# EFR32FG23B010F512IM48 register map
Vendor: Silicon Labs; Series: EFR32; File version: C
CPU: CM33 r0p4, little endian, MPU, FPU, DSP, VTOR, 4 interrupt priority bits, 8 SAU regions
Registers are 32-bit, read-write, reset 0x0 unless marked. A register's access mark holds for its fields unless they carry their own. Offsets are from the block's base; [hi:lo] are bit positions; 'fields as' and 'values as' point back to an identical list.

## DCDC_NS — DCDC_NS Registers
Base 0x50094000
Same registers: DCDC_S 0x40094000
0x00 IPVERSION ro reset 0x1
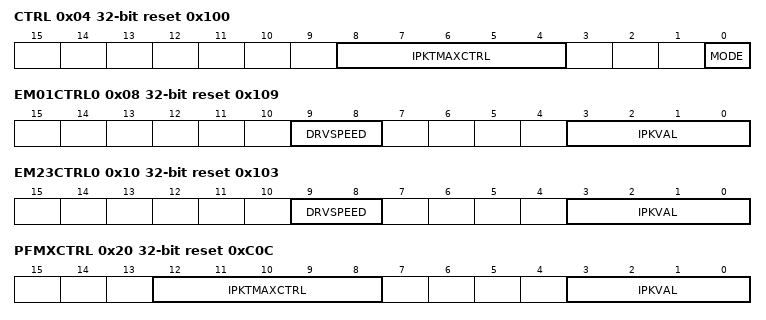
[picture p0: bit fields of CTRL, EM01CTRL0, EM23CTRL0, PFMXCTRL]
0x04 CTRL reset 0x100 — Control
  [8:4] IPKTMAXCTRL — Ton_max timeout control
  [0] MODE — DCDC/Bypass Mode Control
    0=BYPASS (DCDC is OFF, bypass switch is enabled); 1=DCDCREGULATION (Request DCDC regulation, bypass switch disabled)
0x08 EM01CTRL0 reset 0x109 — EM01 Configurations
  [9:8] DRVSPEED — EM01 Drive Speed Setting
    0=BEST_EMI (Not recommended for use (no benefit to this setting)); 1=DEFAULT_SETTING (Recommended for use for best efficiency and low EMI); 2=INTERMEDIATE (Not recommended for use (no benefit to this setting)); 3=BEST_EFFICIENCY (Not recommended for use (no benefit to this setting))
  [3:0] IPKVAL — EM01 Peak Current Setting
    3=Load36mA (Ipeak = 90mA, Iload = 36mA); 4=Load40mA (Ipeak = 100mA, Iload = 40mA); 5=Load44mA (Ipeak = 110mA, Iload = 44mA); 6=Load48mA (Ipeak = 120mA, Iload = 48mA); 7=Load52mA (Ipeak = 130mA, Iload = 52mA); 8=Load56mA (Ipeak = 140mA, Iload = 56mA); 9=Load60mA (Ipeak = 150mA, Iload = 60mA)
0x10 EM23CTRL0 reset 0x103 — EM23 Configurations
  [9:8] DRVSPEED — EM23 Drive Speed Setting
    values as EM01CTRL0.DRVSPEED
  [3:0] IPKVAL — EM23 Peak Current Setting
    3=Load5mA (Ipeak = 90mA, Iload = 5 mA); 9=Load10mA (Ipeak = 150mA, Iload = 10 mA)
0x20 PFMXCTRL reset 0xC0C — PFMX Control Register
  [12:8] IPKTMAXCTRL — Ton_max timeout control
  [3:0] IPKVAL — PFMX mode Peak Current Setting
    3=LOAD50MA (Ipeak = 90 mA, Iload = 50 mA); 4=LOAD65MA (Ipeak = 100 mA, Iload = 65 mA); 5=LOAD73MA (Ipeak = 110 mA, Iload = 73 mA); 6=LOAD80MA (Ipeak = 120 mA, Iload = 80 mA); 7=LOAD86MA (Ipeak = 130 mA, Iload = 86 mA); 8=LOAD93MA (Ipeak = 140 mA, Iload = 93 mA); 9=LOAD100MA (Ipeak = 150 mA, Iload = 100 mA); 10=LOAD106MA (Ipeak = 160 mA, Iload = 106 mA); 11=LOAD113MA (Ipeak = 170 mA, Iload = 113 mA); 12=LOAD120MA (Ipeak = 180 mA, Iload = 120 mA)
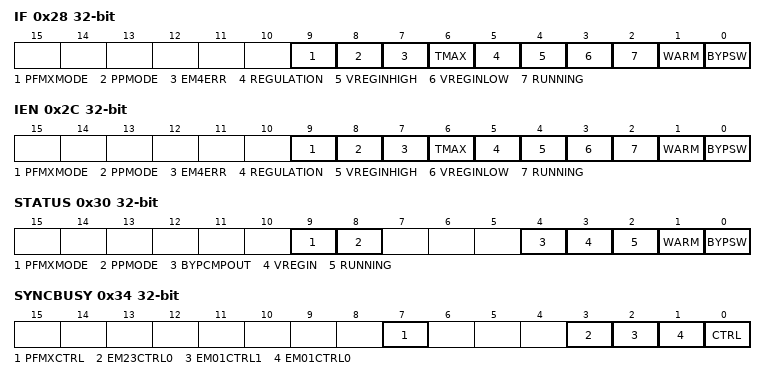
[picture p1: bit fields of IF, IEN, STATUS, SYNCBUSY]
0x28 IF — Interrupt Flags
  [9] PFMXMODE — Entered PFMX mode
  [8] PPMODE — Entered Pulse Pairing mode
  [7] EM4ERR — EM4 Entry Request Error
  [6] TMAX — Ton_max Timeout Reached
  [5] REGULATION — DCDC in regulation
  [4] VREGINHIGH — VREGIN above threshold
  [3] VREGINLOW — VREGIN below threshold
  [2] RUNNING — DCDC Running
  [1] WARM — DCDC Warmup Time Done
  [0] BYPSW — Bypass Switch Enabled
0x2C IEN — Interrupt Enable
  [9] PFMXMODE — PFMX Mode Interrupt Enable
  [8] PPMODE — Pulse Pairing Mode Interrupt Enable
  [7] EM4ERR — EM4 Entry Req Interrupt Enable
  [6] TMAX — Ton_max Timeout Interrupt Enable
  [5] REGULATION — DCDC in Regulation Interrupt Enable
  [4] VREGINHIGH — VREGIN above threshold Interrupt Enable
  [3] VREGINLOW — VREGIN below threshold Interrupt Enable
  [2] RUNNING — DCDC Running Interrupt Enable
  [1] WARM — DCDC Warmup Time Done Interrupt Enable
  [0] BYPSW — Bypass Switch Enabled Interrupt Enable
0x30 STATUS ro — DCDC Status Register
  [9] PFMXMODE — DCDC in PFMX mode
  [8] PPMODE — DCDC in pulse-pairing mode
  [4] BYPCMPOUT — Bypass Comparator Output
  [3] VREGIN — VREGVDD comparator status
  [2] RUNNING — DCDC is running
  [1] WARM — DCDC Warmup Done
  [0] BYPSW — Bypass Switch is currently enabled
0x34 SYNCBUSY ro — Syncbusy Status Register
  [7] PFMXCTRL — PFMXCTRL Sync Busy Status
  [3] EM23CTRL0 — EM23CTRL0 Sync Busy Status
  [2] EM01CTRL1 — EM01CTRL1 Sync Bust Status
  [1] EM01CTRL0 — EM01CTRL0 Sync Busy Status
  [0] CTRL — CTRL Sync Busy Status
0x40 LOCK wo
  [15:0] LOCKKEY — Configuration Lock Key
    0xABCD=UNLOCKKEY
0x44 LOCKSTATUS ro
  [0] LOCK — Lock Status
    0=UNLOCKED (Unlocked State); 1=LOCKED (LOCKED STATE)
